# mpc_me30 register map
Registers are read-only, no defined reset value unless marked. A register's access mark holds for its fields unless they carry their own. Offsets are from the block's base; lines under a group give offsets from that group; [hi:lo] are bit positions; {n}, {i} and the like mark numbered series; 'fields as' and 'values as' point back to an identical list; <NAME> marks a mode.

## Memory map
0x50091000 MPC size 0x1000 — Memory Protection Controller.

## MPC — Memory Protection Controller.
Base 0x50091000
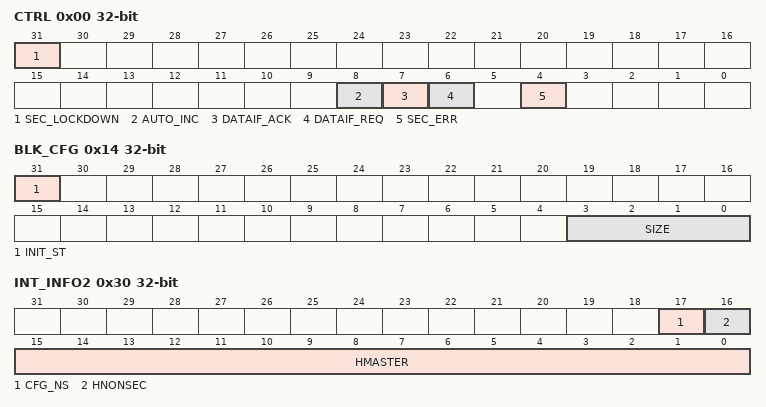
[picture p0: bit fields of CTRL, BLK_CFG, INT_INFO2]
0x00 CTRL 32-bit access not given — Control Register.
  [31] SEC_LOCKDOWN — Security Lockdown.
  [8] AUTO_INC — Auto-increment.
  [7] DATAIF_ACK — Data interface gating acknowledged.
  [6] DATAIF_REQ — Data interface gating request.
  [4] SEC_ERR — Security Error Response COnfiguration.
0x10 BLK_MAX 32-bit — Maximum value of block-based index register.
  [31:0] VAL
0x14 BLK_CFG 32-bit — Block Control Register.
  [31] INIT_ST — Initialization in progress.
  [3:0] SIZE — Block Size.
0x18 BLK_IDX access not given — Block Index Register.
  [31:0] IDX — Index value for accessing block-based lookup table.
0x1C BLK_LUT access not given — Block-based gating Look Up Table Register.
  [31:0] ACCESS — Each bit indicates one block, based on the index pointed by the BLKIDX register.
0x20 INT_STAT — Interrupt Flag Register.
  [0] MPC_IRQ — MPC IRQ triggered.
0x24 INT_CLEAR wo — Interrupt Clear Register.
  [0] MPC_IRQ — MPC IRQ Clear.
0x28 INT_EN access not given — Interrupt Enable Register.
  [0] MPC_IRQ — MPC IRQ Enable.
0x2C INT_INFO1 — Interrupt Info 1 Register.
  [31:0] HADDR — AHB bus signals: Address bus.
0x30 INT_INFO2 — Interrupt Info 2 Register.
  [17] CFG_NS — Security state.
  [16] HNONSEC — AHB bus signals: Indicates the current transfer is either a Non-Secure or Secure transfer.
  [15:0] HMASTER — AHB bus signals: Master Select.
0x34 INT_SET wo — Interrupt Set Debug Register.
  [0] MPC_IRQ — MPC IRQ Set.
{0xFC0+4i} PIDR{i} (i=4..6) — Peripheral ID {i} Register.
0xFDC PIDR7 — Peripheral ID 6 Register.
{0xFE0+4i} PIDR{i} (i=0..3) — Peripheral ID {i} Register.
{0xFF0+4i} CIDR{i} (i=0..3) — Component ID register.
